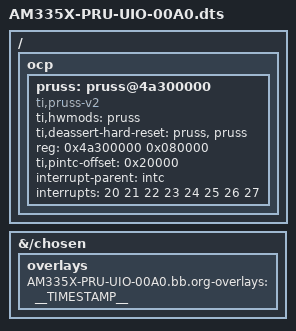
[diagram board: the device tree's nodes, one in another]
// SPDX-License-Identifier: GPL-2.0-only
/*
 * Copyright (C) 2012 Texas Instruments Incorporated - https://www.ti.com/
 */

/dts-v1/;
/plugin/;

/*
 * Helper to show loaded overlays under: /proc/device-tree/chosen/overlays/
 */
&{/chosen} {
	overlays {
		AM335X-PRU-UIO-00A0.bb.org-overlays = __TIMESTAMP__;
	};
};

/ {
	fragment@1 {
		target-path="/";
		__overlay__ {

			ocp {
				#address-cells = <1>;
				#size-cells = <1>;

				pruss: pruss@4a300000 {
					status = "okay";
					compatible = "ti,pruss-v2";
					ti,hwmods = "pruss";
					ti,deassert-hard-reset = "pruss", "pruss";
					reg = <0x4a300000 0x080000>;
					ti,pintc-offset = <0x20000>;
					interrupt-parent = <&intc>;
					interrupts = <20 21 22 23 24 25 26 27>;
				};
			};
		};
	};
};
